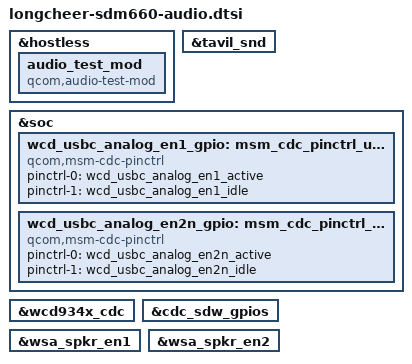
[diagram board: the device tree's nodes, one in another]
// SPDX-License-Identifier: GPL-2.0-only

#include "longcheer-sdm636-audio.dtsi"

&hostless {
	audio_test_mod {
		compatible = "qcom,audio-test-mod";
	};
};

&tavil_snd {
	/delete-property/ qcom,usbc-analog-en1_gpio;
	/delete-property/ qcom,usbc-analog-en2_n_gpio;
};

&soc {
	wcd_usbc_analog_en1_gpio: msm_cdc_pinctrl_usbc_audio_en1 {
		compatible = "qcom,msm-cdc-pinctrl";
		pinctrl-names = "aud_active", "aud_sleep";
		pinctrl-0 = <&wcd_usbc_analog_en1_active>;
		pinctrl-1 = <&wcd_usbc_analog_en1_idle>;
	};

	wcd_usbc_analog_en2n_gpio: msm_cdc_pinctrl_usbc_audio_en2 {
		compatible = "qcom,msm-cdc-pinctrl";
		pinctrl-names = "aud_active", "aud_sleep";
		pinctrl-0 = <&wcd_usbc_analog_en2n_active>;
		pinctrl-1 = <&wcd_usbc_analog_en2n_idle>;
	};
};

&wcd934x_cdc {
	/delete-node/ msm_cdc_pinctrl_usbc_audio_en1;
	/delete-node/ msm_cdc_pinctrl_usbc_audio_en2;
};

/* diff with sdm660-audio.dtsi */
&cdc_sdw_gpios {
	/delete-property/ pinctrl-names;
	/delete-property/ pinctrl-0;
	/delete-property/ pinctrl-1;
};

&wsa_spkr_en1 {
	/delete-property/ pinctrl-names;
	/delete-property/ pinctrl-0;
	/delete-property/ pinctrl-1;
};

&wsa_spkr_en2 {
	/delete-property/ pinctrl-names;
	/delete-property/ pinctrl-0;
	/delete-property/ pinctrl-1;
};

